VERSION ""

NS_ :

BS_:

BU_: DBG VCU BMS MCM DCU DAQ S2C

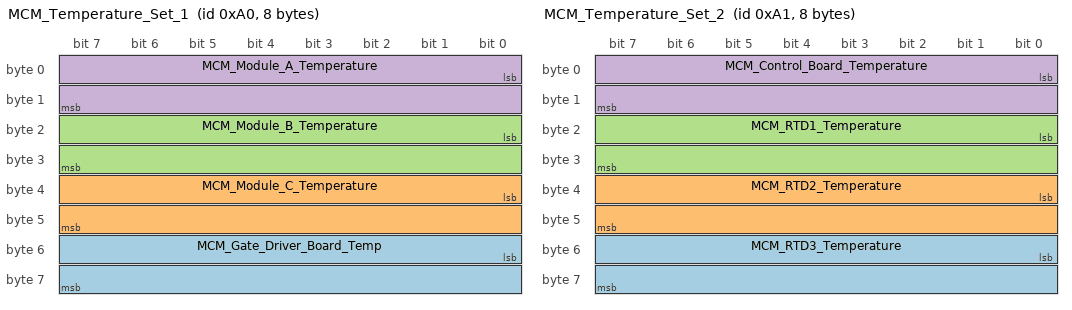
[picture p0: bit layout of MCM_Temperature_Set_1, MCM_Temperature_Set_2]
BO_ 160 MCM_Temperature_Set_1: 8 MCM
 SG_ MCM_Gate_Driver_Board_Temp : 48|16@1- (0.1,0) [-3276.8|3276.7] "C" VCU
 SG_ MCM_Module_C_Temperature : 32|16@1- (0.1,0) [-3276.8|3276.7] "C" VCU
 SG_ MCM_Module_B_Temperature : 16|16@1- (0.1,0) [-3276.8|3276.7] "C" VCU
 SG_ MCM_Module_A_Temperature : 0|16@1- (0.1,0) [-3276.8|3276.7] "C" VCU

BO_ 161 MCM_Temperature_Set_2: 8 MCM
 SG_ MCM_RTD3_Temperature : 48|16@1- (0.1,0) [-3276.8|3276.7] "C" VCU
 SG_ MCM_RTD2_Temperature : 32|16@1- (0.1,0) [-3276.8|3276.7] "C" VCU
 SG_ MCM_RTD1_Temperature : 16|16@1- (0.1,0) [-3276.8|3276.7] "C" VCU
 SG_ MCM_Control_Board_Temperature : 0|16@1- (0.1,0) [-3276.8|3276.7] "C" VCU

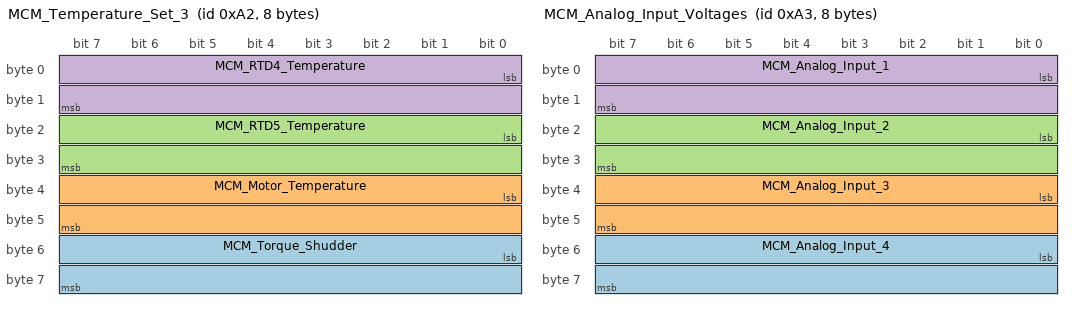
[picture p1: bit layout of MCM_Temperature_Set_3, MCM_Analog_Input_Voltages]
BO_ 162 MCM_Temperature_Set_3: 8 MCM
 SG_ MCM_Torque_Shudder : 48|16@1- (0.1,0) [-3276.8|3276.7] "Nm" VCU
 SG_ MCM_Motor_Temperature : 32|16@1- (0.1,0) [-3276.8|3276.7] "C" VCU
 SG_ MCM_RTD5_Temperature : 16|16@1- (0.1,0) [-3276.8|3276.7] "C" VCU
 SG_ MCM_RTD4_Temperature : 0|16@1- (0.1,0) [-3276.8|3276.7] "C" VCU

BO_ 163 MCM_Analog_Input_Voltages: 8 MCM
 SG_ MCM_Analog_Input_4 : 48|16@1- (0.01,0) [-327.68|327.67] "V" VCU
 SG_ MCM_Analog_Input_3 : 32|16@1- (0.01,0) [-327.68|327.67] "V" VCU
 SG_ MCM_Analog_Input_2 : 16|16@1- (0.01,0) [-327.68|327.67] "V" VCU
 SG_ MCM_Analog_Input_1 : 0|16@1- (0.01,0) [-327.68|327.67] "V" VCU

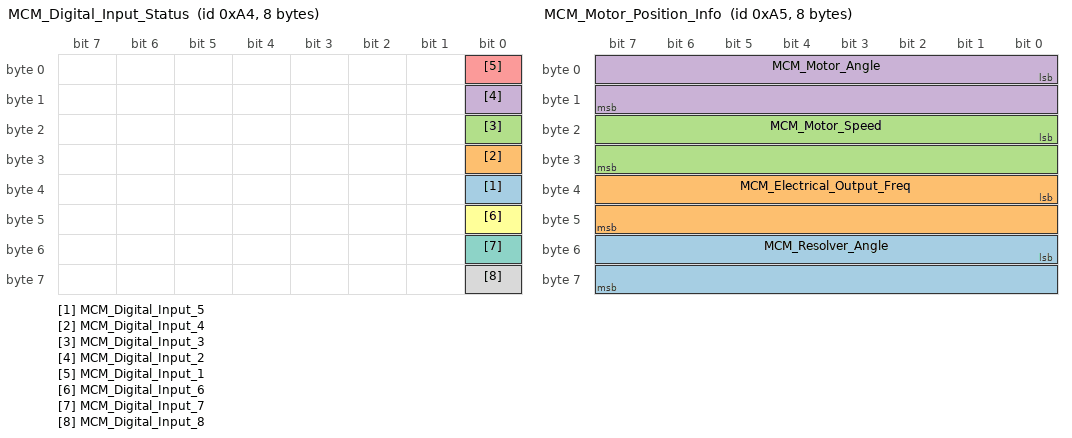
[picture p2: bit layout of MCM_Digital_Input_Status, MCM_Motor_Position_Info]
BO_ 164 MCM_Digital_Input_Status: 8 MCM
 SG_ MCM_Digital_Input_5 : 32|1@1+ (1,0) [0|1] "boolean" VCU
 SG_ MCM_Digital_Input_4 : 24|1@1+ (1,0) [0|1] "boolean" VCU
 SG_ MCM_Digital_Input_3 : 16|1@1+ (1,0) [0|1] "boolean" VCU
 SG_ MCM_Digital_Input_2 : 8|1@1+ (1,0) [0|1] "boolean" VCU
 SG_ MCM_Digital_Input_1 : 0|1@1+ (1,0) [0|1] "boolean" VCU
 SG_ MCM_Digital_Input_6 : 40|1@1+ (1,0) [0|1] "boolean" VCU
 SG_ MCM_Digital_Input_7 : 48|1@1+ (1,0) [0|1] "boolean" VCU
 SG_ MCM_Digital_Input_8 : 56|1@1+ (1,0) [0|1] "boolean" VCU

BO_ 165 MCM_Motor_Position_Info: 8 MCM
 SG_ MCM_Resolver_Angle : 48|16@1- (0.1,0) [-3276.8|3276.7] "DEG" VCU
 SG_ MCM_Electrical_Output_Freq : 32|16@1- (0.1,0) [-3276.8|3276.7] "Hz" VCU
 SG_ MCM_Motor_Speed : 16|16@1- (1,0) [-32768|32767] "RPM" VCU
 SG_ MCM_Motor_Angle : 0|16@1+ (0.1,0) [0|6553.5] "DEG" VCU

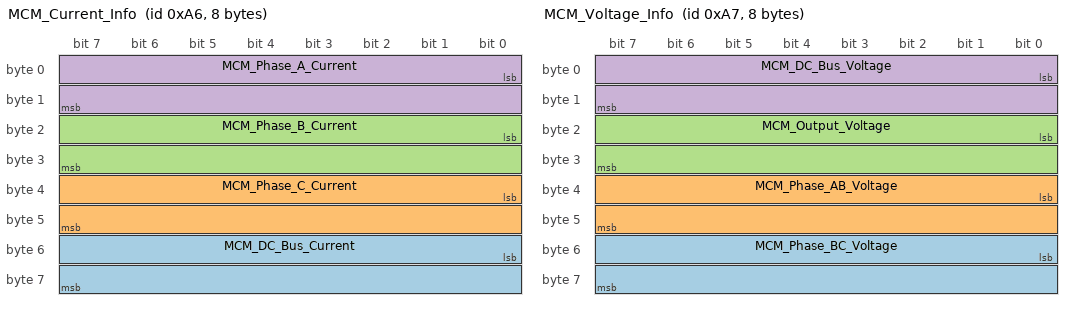
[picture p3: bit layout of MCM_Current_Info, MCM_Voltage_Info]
BO_ 166 MCM_Current_Info: 8 MCM
 SG_ MCM_DC_Bus_Current : 48|16@1- (0.1,0) [-3276.8|3276.7] "A" VCU
 SG_ MCM_Phase_C_Current : 32|16@1- (0.1,0) [-3276.8|3276.7] "A" VCU
 SG_ MCM_Phase_B_Current : 16|16@1- (0.1,0) [-3276.8|3276.7] "A" VCU
 SG_ MCM_Phase_A_Current : 0|16@1- (0.1,0) [-3276.8|3276.7] "A" VCU

BO_ 167 MCM_Voltage_Info: 8 MCM
 SG_ MCM_Phase_BC_Voltage : 48|16@1- (0.1,0) [-3276.8|3276.7] "V" VCU
 SG_ MCM_Phase_AB_Voltage : 32|16@1- (0.1,0) [-3276.8|3276.7] "V" VCU
 SG_ MCM_Output_Voltage : 16|16@1- (0.1,0) [-3276.8|3276.7] "V" VCU
 SG_ MCM_DC_Bus_Voltage : 0|16@1- (0.1,0) [-3276.8|3276.7] "V" VCU

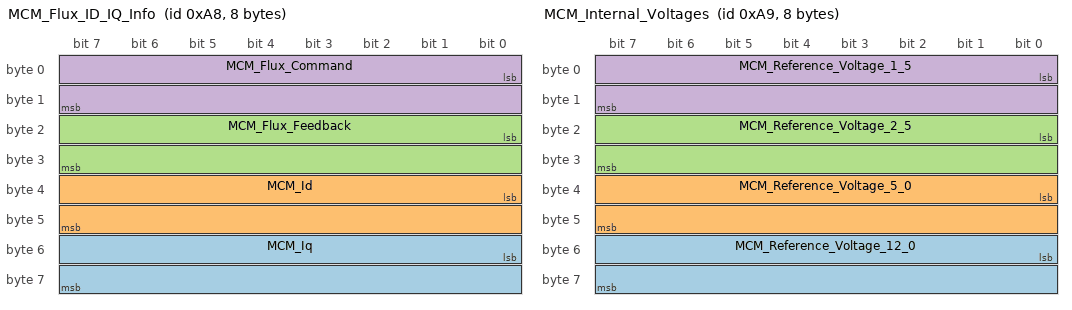
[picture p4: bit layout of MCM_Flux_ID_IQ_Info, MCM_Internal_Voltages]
BO_ 168 MCM_Flux_ID_IQ_Info: 8 MCM
 SG_ MCM_Iq : 48|16@1- (0.1,0) [-3276.8|3276.7] "A" VCU
 SG_ MCM_Id : 32|16@1- (0.1,0) [-3276.8|3276.7] "A" VCU
 SG_ MCM_Flux_Feedback : 16|16@1- (0.001,0) [-32.768|32.767] "Wb" VCU
 SG_ MCM_Flux_Command : 0|16@1- (0.001,0) [-32.768|32.767] "Wb" VCU

BO_ 169 MCM_Internal_Voltages: 8 MCM
 SG_ MCM_Reference_Voltage_12_0 : 48|16@1- (0.01,0) [-327.68|327.67] "V" VCU
 SG_ MCM_Reference_Voltage_5_0 : 32|16@1- (0.01,0) [-327.68|327.67] "V" VCU
 SG_ MCM_Reference_Voltage_2_5 : 16|16@1- (0.01,0) [-327.68|327.67] "V" VCU
 SG_ MCM_Reference_Voltage_1_5 : 0|16@1- (0.01,0) [-327.68|327.67] "V" VCU

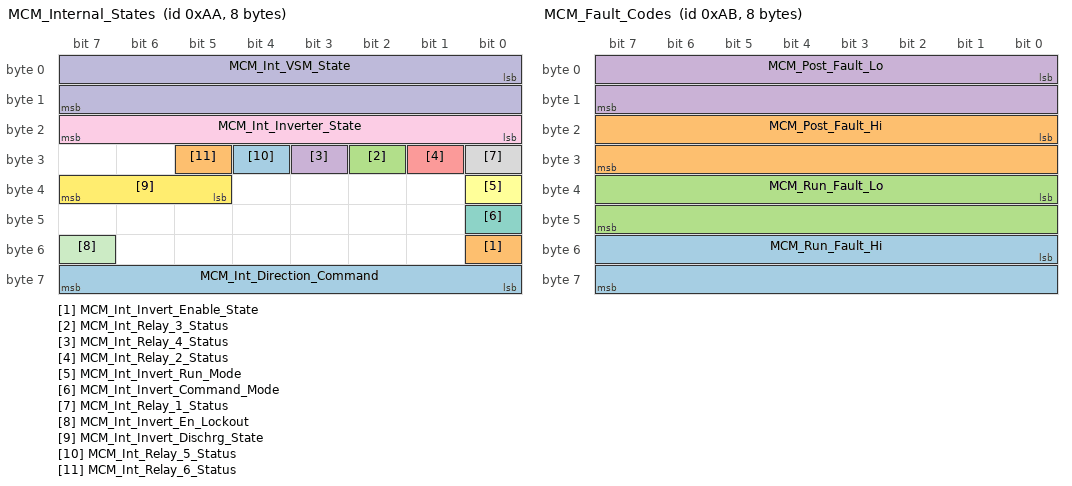
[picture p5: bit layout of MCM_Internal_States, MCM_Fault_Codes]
BO_ 170 MCM_Internal_States: 8 MCM
 SG_ MCM_Int_Direction_Command : 56|8@1+ (1,0) [0|1] "" MCM
 SG_ MCM_Int_Invert_Enable_State : 48|1@1+ (1,0) [0|1] "" MCM
 SG_ MCM_Int_Relay_3_Status : 26|1@1+ (1,0) [0|1] "" MCM
 SG_ MCM_Int_Relay_4_Status : 27|1@1+ (1,0) [0|1] "" MCM
 SG_ MCM_Int_Relay_2_Status : 25|1@1+ (1,0) [0|1] "" MCM
 SG_ MCM_Int_Invert_Run_Mode : 32|1@1+ (1,0) [0|1] "" MCM
 SG_ MCM_Int_Invert_Command_Mode : 40|1@1+ (1,0) [0|1] "" MCM
 SG_ MCM_Int_Relay_1_Status : 24|1@1+ (1,0) [0|1] "" MCM
 SG_ MCM_Int_Inverter_State : 16|8@1+ (1,0) [0|255] "" MCM
 SG_ MCM_Int_VSM_State : 0|16@1+ (1,0) [0|15] "" MCM
 SG_ MCM_Int_Invert_En_Lockout : 55|1@1+ (1,0) [0|1] "" MCM
 SG_ MCM_Int_Invert_Dischrg_State : 37|3@1+ (1,0) [0|7] "" MCM
 SG_ MCM_Int_Relay_5_Status : 28|1@1+ (1,0) [0|1] "" MCM
 SG_ MCM_Int_Relay_6_Status : 29|1@1+ (1,0) [0|1] "" MCM

BO_ 171 MCM_Fault_Codes: 8 MCM
 SG_ MCM_Run_Fault_Hi : 48|16@1+ (1,0) [0|65535] "" VCU
 SG_ MCM_Post_Fault_Hi : 16|16@1+ (1,0) [0|65535] "" VCU
 SG_ MCM_Run_Fault_Lo : 32|16@1+ (1,0) [0|65535] "" VCU
 SG_ MCM_Post_Fault_Lo : 0|16@1+ (1,0) [0|65535] "" VCU

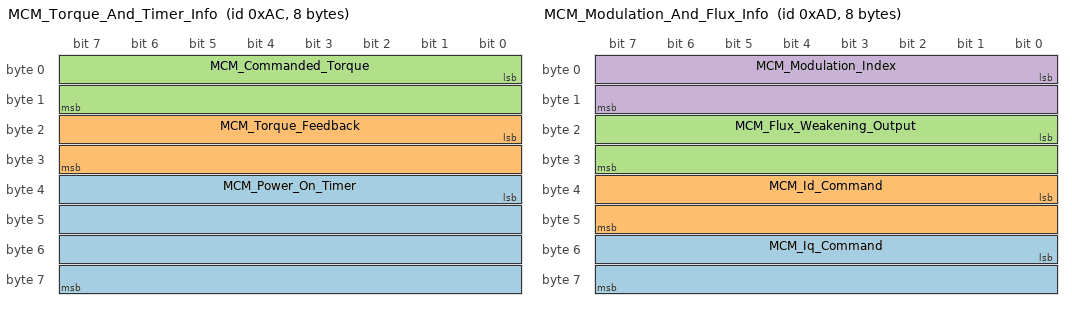
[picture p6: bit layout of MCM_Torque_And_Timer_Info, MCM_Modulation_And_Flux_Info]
BO_ 172 MCM_Torque_And_Timer_Info: 8 MCM
 SG_ MCM_Power_On_Timer : 32|32@1+ (0.003,0) [0|12884800] "Sec" VCU
 SG_ MCM_Torque_Feedback : 16|16@1- (0.1,0) [-3276.8|3276.7] "Nm" VCU
 SG_ MCM_Commanded_Torque : 0|16@1- (0.1,0) [-3276.8|3276.7] "Nm" VCU

BO_ 173 MCM_Modulation_And_Flux_Info: 8 MCM
 SG_ MCM_Iq_Command : 48|16@1- (0.1,0) [-3276.8|3276.7] "A" VCU
 SG_ MCM_Id_Command : 32|16@1- (0.1,0) [-3276.8|3276.7] "A" VCU
 SG_ MCM_Flux_Weakening_Output : 16|16@1- (0.1,0) [-3276.8|3276.7] "A" VCU
 SG_ MCM_Modulation_Index : 0|16@1- (0.0001,0) [-3.2768|3.2767] "" VCU

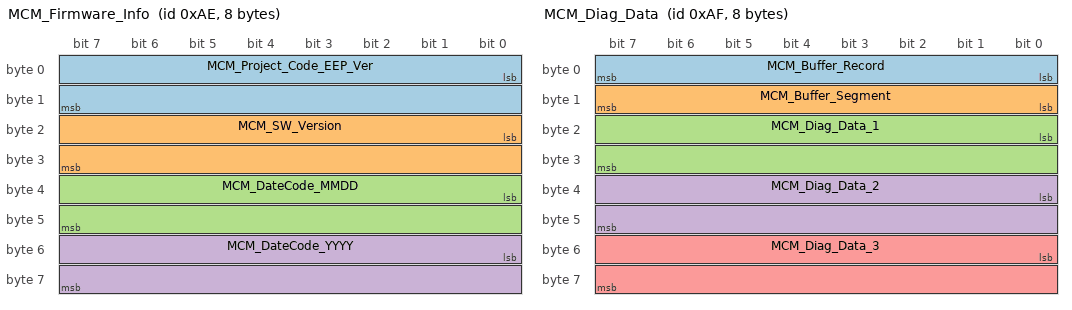
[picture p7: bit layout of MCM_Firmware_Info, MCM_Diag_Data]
BO_ 174 MCM_Firmware_Info: 8 MCM
 SG_ MCM_Project_Code_EEP_Ver : 0|16@1+ (1,0) [0|65535] "" VCU
 SG_ MCM_SW_Version : 16|16@1+ (1,0) [0|65535] "" VCU
 SG_ MCM_DateCode_MMDD : 32|16@1+ (1,0) [0|65535] "" VCU
 SG_ MCM_DateCode_YYYY : 48|16@1+ (1,0) [0|65535] "" VCU

BO_ 175 MCM_Diag_Data: 8 MCM
 SG_ MCM_Buffer_Record : 0|8@1+ (1,0) [0|255] "" VCU
 SG_ MCM_Buffer_Segment : 8|8@1+ (1,0) [0|5] "" VCU
 SG_ MCM_Diag_Data_1 : 16|16@1- (1,0) [-32768|32767] "" VCU
 SG_ MCM_Diag_Data_2 : 32|16@1- (1,0) [-32768|32767] "" VCU
 SG_ MCM_Diag_Data_3 : 48|16@1- (1,0) [-32768|32767] "" VCU

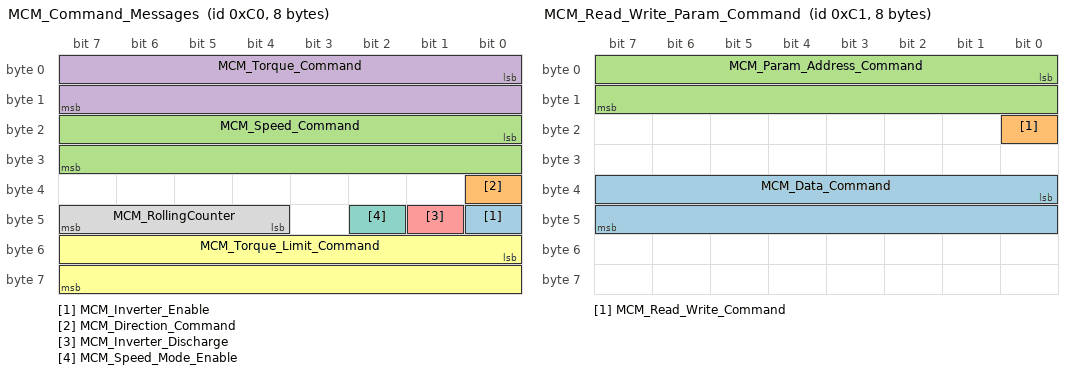
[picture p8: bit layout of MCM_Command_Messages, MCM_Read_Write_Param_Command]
BO_ 192 MCM_Command_Messages: 8 VCU
 SG_ MCM_Inverter_Enable : 40|1@1+ (1,0) [0|1] "" MCM
 SG_ MCM_Direction_Command : 32|1@1+ (1,0) [0|1] "" MCM
 SG_ MCM_Speed_Command : 16|16@1- (1,0) [-32768|32767] "rpm" MCM
 SG_ MCM_Torque_Command : 0|16@1- (0.1,0) [-3276.8|3276.7] "Nm" MCM
 SG_ MCM_Inverter_Discharge : 41|1@1+ (1,0) [0|1] "" MCM
 SG_ MCM_Torque_Limit_Command : 48|16@1- (0.1,0) [-3276.8|3276.7] "Nm" MCM
 SG_ MCM_Speed_Mode_Enable : 42|1@1+ (1,0) [0|1] "" MCM
 SG_ MCM_RollingCounter : 44|4@1+ (1,0) [0|15] "" MCM

BO_ 193 MCM_Read_Write_Param_Command: 8 VCU
 SG_ MCM_Data_Command : 32|16@1- (1,0) [-32768|32767] "" VCU
 SG_ MCM_Read_Write_Command : 16|1@1+ (1,0) [0|1] "" VCU
 SG_ MCM_Param_Address_Command : 0|16@1+ (1,0) [0|65535] "" VCU

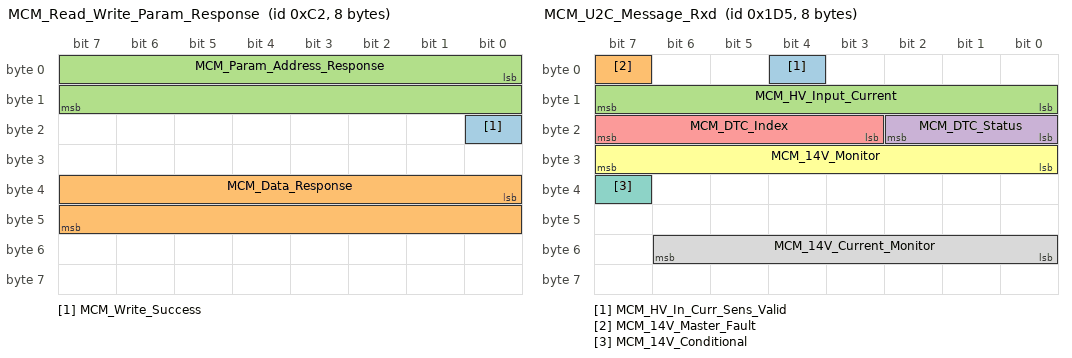
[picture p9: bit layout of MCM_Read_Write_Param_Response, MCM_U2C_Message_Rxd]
BO_ 194 MCM_Read_Write_Param_Response: 8 VCU
 SG_ MCM_Write_Success : 16|1@1+ (1,0) [0|1] "" VCU
 SG_ MCM_Data_Response : 32|16@1- (1,0) [-32768|32767] "" VCU
 SG_ MCM_Param_Address_Response : 0|16@1+ (1,0) [0|65535] "" VCU

BO_ 469 MCM_U2C_Message_Rxd: 8 MCM
 SG_ MCM_HV_In_Curr_Sens_Valid : 4|1@1+ (1,0) [0|1] "" VCU
 SG_ MCM_14V_Master_Fault : 7|1@1+ (1,0) [0|1] "" VCU
 SG_ MCM_HV_Input_Current : 8|8@1+ (1,0) [0|255] "" VCU
 SG_ MCM_DTC_Status : 16|3@1+ (1,0) [0|7] "" VCU
 SG_ MCM_DTC_Index : 19|5@1+ (1,0) [0|31] "" VCU
 SG_ MCM_14V_Monitor : 24|8@1+ (1,0) [0|255] "" VCU
 SG_ MCM_14V_Conditional : 39|1@1+ (1,0) [0|1] "" VCU
 SG_ MCM_14V_Current_Monitor : 48|7@1+ (1,0) [0|127] "" VCU

BO_ 471 MCM_U2C_Command_Txd: 8 MCM
 SG_ MCM_ID_Byte : 0|8@1+ (1,0) [0|255] "" VCU
 SG_ MCM_Setpoint_Calc : 8|8@1+ (1,0) [0|255] "" VCU

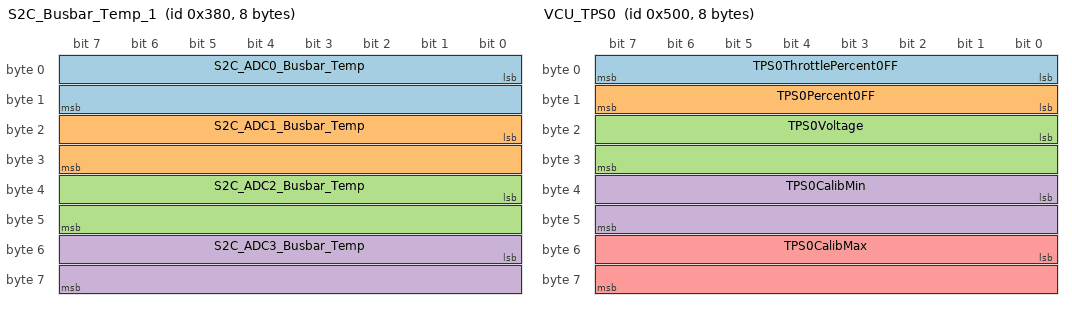
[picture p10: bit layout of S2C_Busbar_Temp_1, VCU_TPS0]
BO_ 896 S2C_Busbar_Temp_1: 8 DAQ
 SG_ S2C_ADC0_Busbar_Temp : 0|16@1+ (0.01,0) [0|65535] "C" S2C
 SG_ S2C_ADC1_Busbar_Temp : 16|16@1+ (0.01,0) [0|65535] "C" S2C
 SG_ S2C_ADC2_Busbar_Temp : 32|16@1+ (0.01,0) [0|65535] "C" S2C
 SG_ S2C_ADC3_Busbar_Temp : 48|16@1+ (0.01,0) [0|65535] "C" S2C

BO_ 1280 VCU_TPS0: 8 VCU
 SG_ TPS0ThrottlePercent0FF : 0|8@1+ (0.392156862746,0) [0|100.00000000023] "%" VCU
 SG_ TPS0Percent0FF : 8|8@1+ (0.392156862746,0) [0|100.00000000023] "%" VCU
 SG_ TPS0Voltage : 16|16@1+ (0.001,0) [0|65.535] "V" VCU
 SG_ TPS0CalibMin : 32|16@1+ (0.001,0) [0|65.535] "V" VCU
 SG_ TPS0CalibMax : 48|16@1+ (0.001,0) [0|65.535] "V" VCU

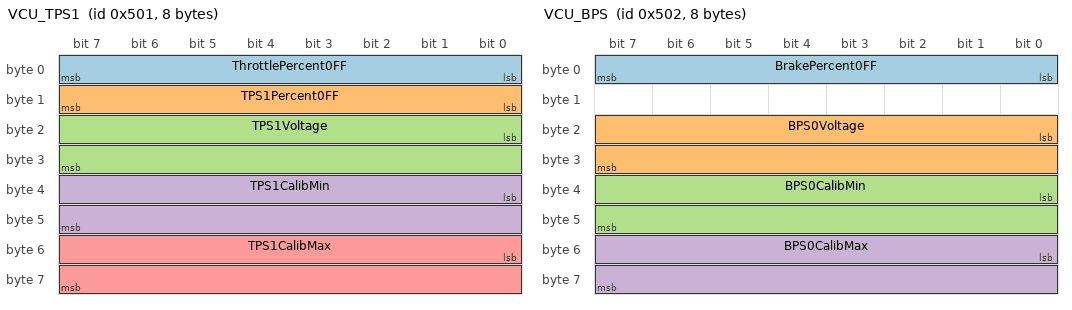
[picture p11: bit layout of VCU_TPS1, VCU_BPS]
BO_ 1281 VCU_TPS1: 8 VCU
 SG_ ThrottlePercent0FF : 0|8@1+ (1,0) [0|255] "" VCU
 SG_ TPS1Percent0FF : 8|8@1+ (0.392156862746,0) [0|100.00000000023] "%" VCU
 SG_ TPS1Voltage : 16|16@1+ (0.001,0) [0|65.535] "V" VCU
 SG_ TPS1CalibMin : 32|16@1+ (0.001,0) [0|65.535] "V" VCU
 SG_ TPS1CalibMax : 48|16@1+ (0.001,0) [0|65.535] "V" VCU

BO_ 1282 VCU_BPS: 8 VCU
SG_ BrakePercent0FF : 0|8@1+ (0.392156862746,0) [0|100.00000000023] "%" VCU
SG_ BPS0Voltage : 16|16@1+ (0.001,0) [0|65.535] "V" VCU
SG_ BPS0CalibMin : 32|16@1+ (0.001,0) [0|65.535] "V" VCU
SG_ BPS0CalibMax : 48|16@1+ (0.001,0) [0|65.535] "V" VCU

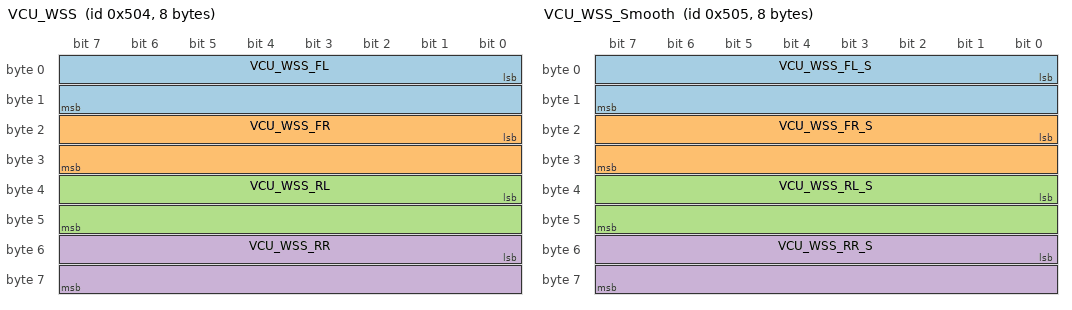
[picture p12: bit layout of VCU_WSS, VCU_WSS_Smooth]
BO_ 1284 VCU_WSS: 8 VCU
 SG_ VCU_WSS_FL : 0|16@1+ (1,0) [0|32767] "RPM" VCU
 SG_ VCU_WSS_FR : 16|16@1+ (1,0) [0|32767] "RPM" VCU
 SG_ VCU_WSS_RL : 32|16@1+ (1,0) [0|32767] "RPM" VCU
 SG_ VCU_WSS_RR : 48|16@1+ (1,0) [0|32767] "RPM" VCU

BO_ 1285 VCU_WSS_Smooth: 8 VCU
 SG_ VCU_WSS_FL_S : 0|16@1+ (1,0) [0|32767] "RPM" VCU
 SG_ VCU_WSS_FR_S : 16|16@1+ (1,0) [0|32767] "RPM" VCU
 SG_ VCU_WSS_RL_S : 32|16@1+ (1,0) [0|32767] "RPM" VCU
 SG_ VCU_WSS_RR_S : 48|16@1+ (1,0) [0|32767] "RPM" VCU

BO_ 1286 VCU_Safety_Checker: 8 VCU
 SG_ VCU_FAULT_TPS_OutOfRange : 0|1@1+ (1,0) [0|1] "" VCU
 SG_ VCU_FAULT_BPS_OutOfRange : 1|1@1+ (1,0) [0|1] "" VCU
 SG_ VCU_FAULT_TPS_PowerFailure : 2|1@1+ (1,0) [0|1] "" VCU
 SG_ VCU_FAULT_BPS_PowerFailure : 3|1@1+ (1,0) [0|1] "" VCU
 SG_ VCU_FAULT_TPS_SignalFailure : 4|1@1+ (1,0) [0|1] "" VCU
 SG_ VCU_FAULT_BPS_SignalFailure : 5|1@1+ (1,0) [0|1] "" VCU
 SG_ VCU_FAULT_TPS_NotCalibrated : 6|1@1+ (1,0) [0|1] "" VCU
 SG_ VCU_FAULT_BPS_NotCalibrated : 7|1@1+ (1,0) [0|1] "" VCU
 SG_ VCU_FAULT_TPS_OutOfSync : 8|1@1+ (1,0) [0|1] "" VCU
 SG_ VCU_FAULT_TPSBPS_Implausible : 10|1@1+ (1,0) [0|1] "" VCU
 SG_ VCU_FAULT_BSPD_SoftFault : 12|1@1+ (1,0) [0|1] "" VCU
 SG_ VCU_FAULT_LVS_BatteryEmpty : 16|1@1+ (1,0) [0|1] "" VCU
 SG_ VCU_WARNING_LVS_BatteryLow : 32|1@1+ (1,0) [0|1] "" VCU
 SG_ VCU_WARNING_HVIL_OverrideEn : 38|1@1+ (1,0) [0|1] "" VCU
 SG_ VCU_WARNING_SAFETY_BypassEn : 39|1@1+ (1,0) [0|1] "" VCU
 SG_ VCU_NOTICE_HVIL_TermSenseLost : 48|1@1+ (1,0) [0|1] "" VCU
 SG_ VCU_NOTICE_BMS_Over75kW : 52|1@1+ (1,0) [0|1] "" VCU
 SG_ VCU_NOTICE_MCM_Over75kW : 53|1@1+ (1,0) [0|1] "" VCU

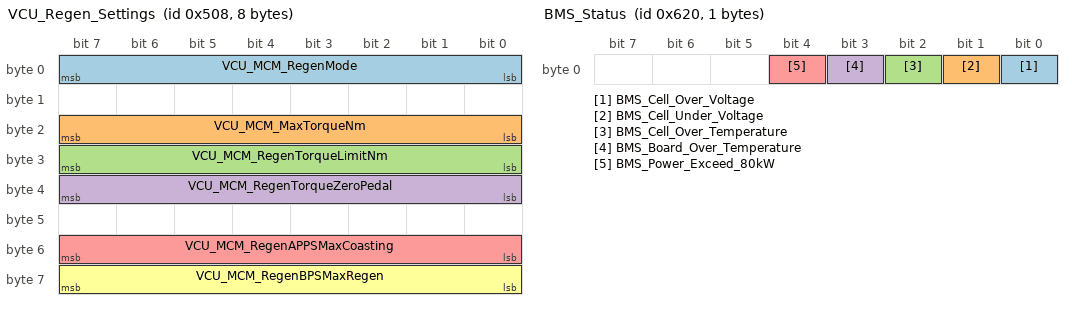
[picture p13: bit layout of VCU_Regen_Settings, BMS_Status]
BO_ 1288 VCU_Regen_Settings: 8 VCU
 SG_ VCU_MCM_RegenMode : 0|8@1+ (1,0) [0|255] "" VCU
 SG_ VCU_MCM_MaxTorqueNm : 16|8@1+ (1,0) [0|255] "Nm" VCU
 SG_ VCU_MCM_RegenTorqueLimitNm : 24|8@1+ (1,0) [0|255] "Nm" VCU
 SG_ VCU_MCM_RegenTorqueZeroPedal : 32|8@1+ (1,0) [0|255] "Nm" VCU
 SG_ VCU_MCM_RegenAPPSMaxCoasting : 48|8@1+ (1,0) [0|255] "" VCU
 SG_ VCU_MCM_RegenBPSMaxRegen : 56|8@1+ (1,0) [0|255] "" VCU

BO_ 1568 BMS_Status: 1 BMS
 SG_ BMS_Cell_Over_Voltage : 0|1@1+ (1,0) [0|0] "" VCU
 SG_ BMS_Cell_Under_Voltage : 1|1@1+ (1,0) [0|0] "" VCU
 SG_ BMS_Cell_Over_Temperature : 2|1@1+ (1,0) [0|0] "" VCU
 SG_ BMS_Board_Over_Temperature : 3|1@1+ (1,0) [0|0] "" VCU
 SG_ BMS_Power_Exceed_80kW : 4|1@1+ (1,0) [0|0] "" VCU

BO_ 1571 BMS_Pack_Info: 8 BMS
 SG_ BMS_Pack_Voltage : 0|32@1- (0.1,0) [0|300.0] "V" VCU
 SG_ BMS_Pack_Current : 32|32@1- (0.1,-3000) [-3000.0|3000.0] "A" VCU

BO_ 1572 BMS_Load_Info: 8 BMS
 SG_ BMS_Load_Voltage : 0|32@1- (0.01,0) [0|300.0] "V" VCU
 SG_ BMS_Load_Current : 32|32@1- (0.01,-3000) [-3000.0|3000.0] "A" VCU

BO_ 1573 BMS_Cell_Voltage_High_Low: 8 BMS
 SG_ BMS_Cell_Voltage_High : 0|32@1- (0.01,0) [0|6.55] "V" VCU
 SG_ BMS_Cell_Voltage_Low : 32|32@1- (0.01,0) [0|6.55] "V" VCU

BO_ 1574 BMS_Cell_Voltage_Average: 8 BMS
 SG_ BMS_Cell_Voltage_Average : 0|32@1- (0.01,0) [0|6.55] "V" VCU
 SG_ BMS_Cell_Voltage_Mismatch : 32|32@1- (0.01,0) [0|6.55] "V" VCU

BO_ 1575 BMS_Status_SoC: 8 BMS
 SG_ BMS_SOC : 0|32@1- (0.1,0) [0|100] "%" VCU
 SG_ BMS_Capacity : 32|32@1- (0.1,0) [0|30] "Ah" VCU

BO_ 1576 BMS_Temperature_Average: 8 BMS
 SG_ BMS_Cell_Temperature_Average : 0|32@1- (0.1,0) [-100.0|100.0] "C" VCU
 SG_ BMS_Board_Temperature_Average : 32|32@1- (0.1,0) [-100.0|100.0] "C" VCU

BO_ 1577 BMS_Cell_Temperature: 8 BMS
 SG_ BMS_Cell_Temperature_High : 0|32@1- (0.1,0) [-99.9|99.9] "C" VCU
 SG_ BMS_Cell_Temperature_Low : 32|32@1- (0.1,0) [-99.9|99.9] "C" VCU

BO_ 1578 BMS_M_Temperature_Average_1: 8 BMS
 SG_ BMS_M1_Temp_Average : 0|32@1- (0.1,0) [-100.0|100.0] "C" VCU
 SG_ BMS_M2_Temp_Average : 32|32@1- (0.1,0) [-100.0|100.0] "C" VCU

BO_ 1579 BMS_M_Temperature_Average_1: 8 BMS
 SG_ BMS_M3_Temp_Average : 0|32@1- (0.1,0) [-100.0|100.0] "C" VCU
 SG_ BMS_M4_Temp_Average : 32|32@1- (0.1,0) [-100.0|100.0] "C" VCU

BO_ 1580 BMS_M_Temperature_Average_1: 8 BMS
 SG_ BMS_M5_Temp_Average : 0|32@1- (0.1,0) [-100.0|100.0] "C" VCU
 SG_ BMS_M6_Temp_Average : 32|32@1- (0.1,0) [-100.0|100.0] "C" VCU

BO_ 1584 BMS_Board_Temperature: 8 BMS
 SG_ BMS_Board_Temperature_High : 0|32@1- (0.1,0) [-100.0|100.0] "C" VCU
 SG_ BMS_Board_Temperature_Low : 32|32@1- (0.1,0) [-100.0|100.0] "C" VCU

BO_ 1585 BMS_Load_Power: 4 BMS
 SG_ BMS_Load_Power : 0|32@1- (0.1,0) [-79999.9|79999.9] "W" VCU

BO_ 1793 DCU_Timestamp: 1 DCU
 SG_ DCU_Timestamp : 0|8@1+ (1,0) [0|255] "" VCU

CM_ BU_ VCU "The vehicle control unit";
CM_ BU_ MCM "The motor controller of the car";
CM_ BU_ BMS "The battery management system";
CM_ BU_ DCU "The dash control unit";
CM_ BO_ 160 "Motor Controller Temperatures Set 1";
CM_ BO_ 161 "Motor Controller Temperatures Set 2";
CM_ BO_ 162 "Motor Controller Temperatures Set 3";
CM_ BO_ 165 "Motor Position Information";
CM_ BO_ 166 "Motor Current Information";
CM_ BO_ 167 "Motor Voltage Information";
CM_ BO_ 192 "Motor Controller Command Messages";
CM_ BO_ 1280 "Throttle Position Sensor 0 Value";
CM_ BO_ 1281 "Throttle Position Sensor 1 Value";
CM_ BO_ 1282 "Brake Pressure Sensor Value";
CM_ BO_ 1283 "Wheel Speed Sensor Value";
CM_ BO_ 1286 "VCU Safety Messages";
CM_ BO_ 1568 "BMS Status and Fault Message";
CM_ BO_ 1571 "Accumulator Pack Voltage and Current";
CM_ BO_ 1572 "Accumulator Load Voltage and Current";
CM_ BO_ 1573 "Cell Voltage High and Low";
CM_ BO_ 1574 "Cell Voltage Average and Mismatch";
CM_ BO_ 1575 "SOC Percentage and Battery Capacity";
CM_ BO_ 1576 "Cell and BMS Board Temperature Average";
CM_ BO_ 1577 "Cell Temperature High and Low";
CM_ BO_ 1584 "BMS Board Temperature High and Low";
CM_ BO_ 1585 "Accumulator Load Power";
CM_ BO_ 1793 "Dash Control Unit Timestamp";

BA_DEF_ "BusType" STRING ;
BA_DEF_ SG_ "FieldType" STRING ;

BA_DEF_DEF_ "BusType" "CAN";
BA_DEF_DEF_ "FieldType" "";

BA_ "FieldType" SG_ 100 DRIVER_HEARTBEAT_cmd "DRIVER_HEARTBEAT_cmd";

VAL_ 100 DRIVER_HEARTBEAT_cmd 2 "DRIVER_HEARTBEAT_cmd_REBOOT" 1 "DRIVER_HEARTBEAT_cmd_SYNC" 0 "DRIVER_HEARTBEAT_cmd_NOOP" ;
